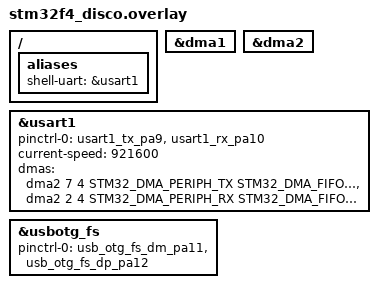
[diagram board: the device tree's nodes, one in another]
#include <dt-bindings/gpio/gpio.h>
#include <dt-bindings/pinctrl/stm32-pinctrl.h>

/ {
	aliases {
		shell-uart = &usart1;
	};
};

&dma1 {
	status = "okay";
};

&dma2 {
	status = "okay";
};

&usart1 {
	pinctrl-0 = <&usart1_tx_pa9 &usart1_rx_pa10>;
	pinctrl-names = "default";
	current-speed = <921600>;
	dmas = <&dma2 7 4 STM32_DMA_PERIPH_TX STM32_DMA_FIFO_FULL>,
	       <&dma2 2 4 STM32_DMA_PERIPH_RX STM32_DMA_FIFO_FULL>;
	dma-names = "tx", "rx";
	status = "okay";
};

&usbotg_fs {
	pinctrl-0 = <&usb_otg_fs_dm_pa11 &usb_otg_fs_dp_pa12>;
	pinctrl-names = "default";
	status = "okay";
};


